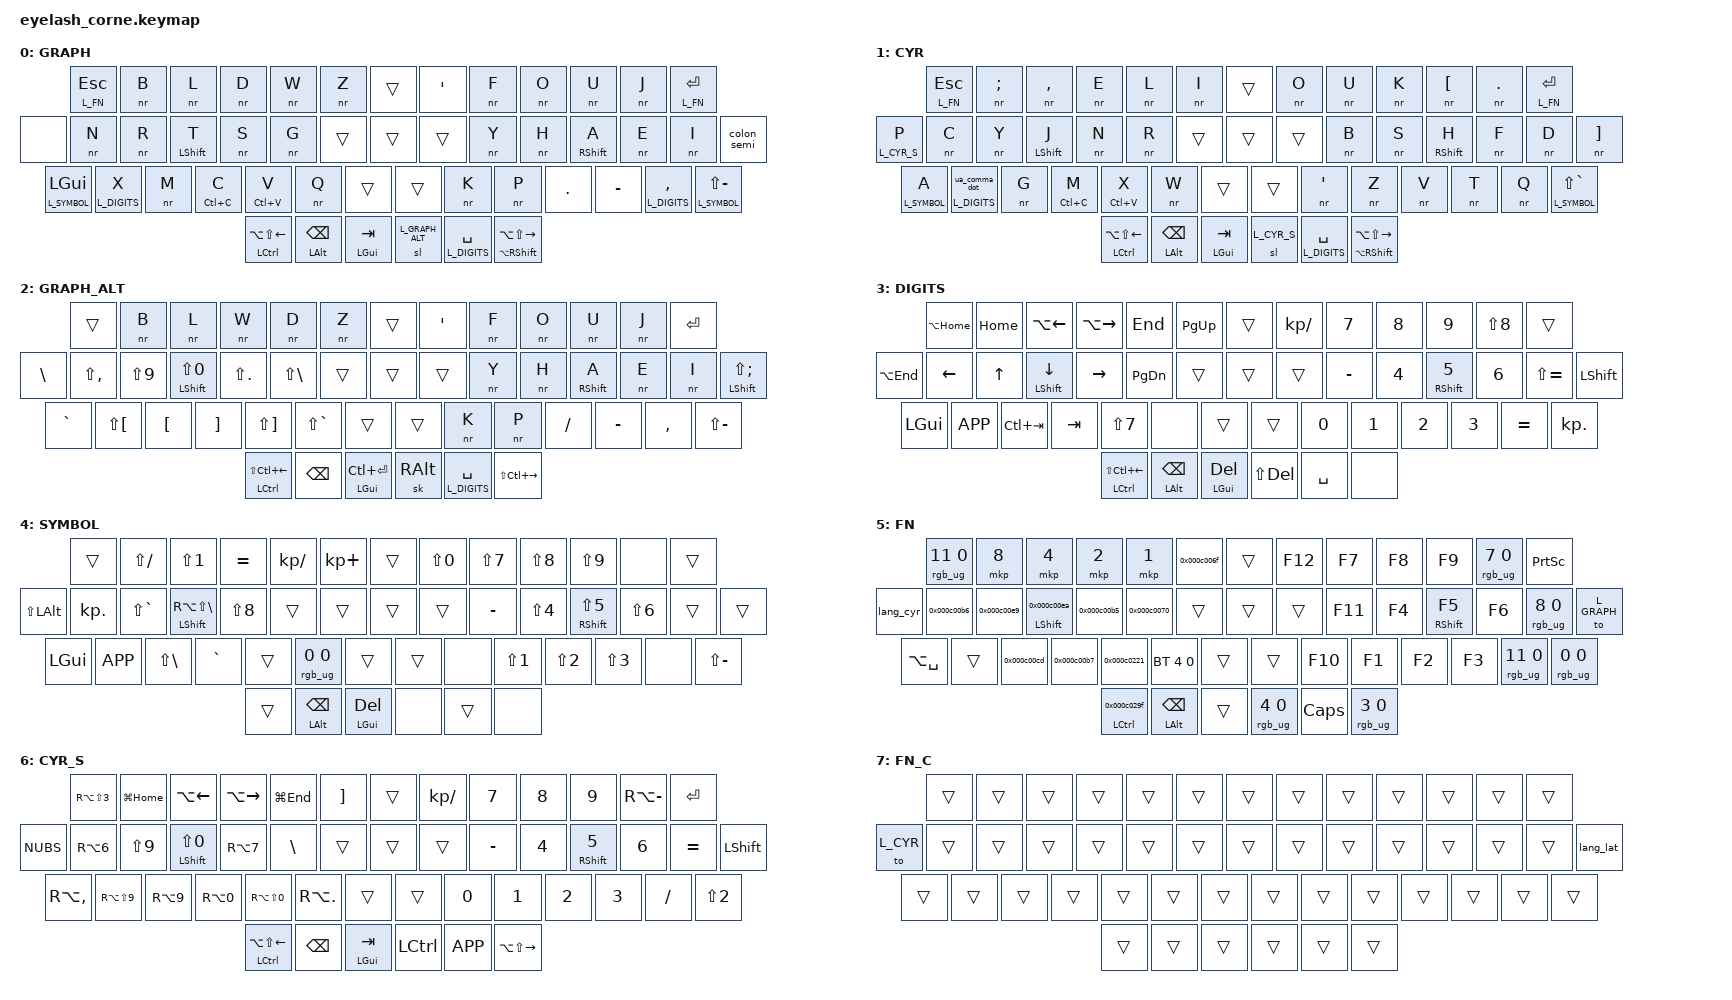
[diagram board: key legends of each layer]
/*
 * Згенеровано layout_dev_project/scripts/zmk/keymap_from_dump.py з дампу
 * клавіатури (ZMK Studio). Порядок шарів = пріоритет (нижчий у списку
 * перекриває вищі): CYR одразу після GRAPH, інакше він ховає DIGITS/SYMBOL/
 * FN/CYR_S. id у #define = позиція тут. 2026-11-17.
 */

#include <behaviors.dtsi>
#include <dt-bindings/zmk/keys.h>
#include <dt-bindings/zmk/bt.h>

#define L_GRAPH      0
#define L_GRAPH_ALT  2
#define L_DIGITS     3
#define L_SYMBOL     4
#define L_FN         5
#define L_CYR_S      6
#define L_CYR        1
#define L_FN_C       7

/ {
    behaviors {
        /* Tap = ESC, Hold = FN layer */
        esc_fn: esc_fn {
            compatible = "zmk,behavior-hold-tap";
            #binding-cells = <2>;
            tapping-term-ms = <200>;
            flavor = "balanced";
            bindings = <&kp>, <&mo>;
        };

        /* Home-row mods: холд лише якщо наступна клавіша на іншій руці / тхамбі
         * (перекат однією рукою = завжди тап) і лише після паузи в друці. */
        hml: home_row_mod_left {
            compatible = "zmk,behavior-hold-tap";
            display-name = "HRM Left";
            #binding-cells = <2>;
            flavor = "balanced";
            tapping-term-ms = <280>;
            quick-tap-ms = <175>;
            require-prior-idle-ms = <150>;
            hold-trigger-key-positions = <7 8 9 10 11 12 22 23 24 25 26 27 36 37 38 39 40 41 42 43 44 45 46 47>;
            hold-trigger-on-release;
            bindings = <&kp>, <&kp>;
        };

        hmr: home_row_mod_right {
            compatible = "zmk,behavior-hold-tap";
            display-name = "HRM Right";
            #binding-cells = <2>;
            flavor = "balanced";
            tapping-term-ms = <280>;
            quick-tap-ms = <175>;
            require-prior-idle-ms = <150>;
            hold-trigger-key-positions = <0 1 2 3 4 5 13 14 15 16 17 18 28 29 30 31 32 33 42 43 44 45 46 47>;
            hold-trigger-on-release;
            bindings = <&kp>, <&kp>;
        };

        /* Кирилиця (ua): тап ",", Shift+тап "." (шифт маскується, xkb ua дає
         * "." на голій FSLH). Стандарт ЙЦУКЕН навпаки — кома частіша. 2026-10-30. */
        ua_comma_dot: ua_comma_dot {
            compatible = "zmk,behavior-mod-morph";
            #binding-cells = <0>;
            bindings = <&kp LS(FSLH)>, <&kp FSLH>;
            mods = <(MOD_LSFT|MOD_RSFT)>;
        };

        /* Кома-крапка з холдом шару (як &lt): &lt_cd ШАР 0 */
        lt_cd: layer_tap_comma_dot {
            compatible = "zmk,behavior-hold-tap";
            display-name = "LT Comma/Dot";
            #binding-cells = <2>;
            flavor = "tap-preferred";
            tapping-term-ms = <200>;
            bindings = <&mo>, <&ua_comma_dot>;
        };

        /* Латиниця (us): тап ":", Shift+тап ";". 2026-10-30. */
        colon_semi: colon_semi {
            compatible = "zmk,behavior-mod-morph";
            display-name = "Colon/Semi";
            #binding-cells = <0>;
            bindings = <&kp LS(SEMI)>, <&kp SEMI>;
            mods = <(MOD_LSFT|MOD_RSFT)>;
        };

    };

    macros {
        /* Літери без автоповтору: на натискання — tap (press+release ~30 мс),
         * ОС не бачить затиснутої клавіші. BSPC/стрілки/пробіл тощо — &kp. 2026-11-17. */
        nr: no_repeat {
            compatible = "zmk,behavior-macro-one-param";
            display-name = "No Repeat";
            #binding-cells = <1>;
            bindings = <&macro_param_1to1 &macro_tap &kp MACRO_PLACEHOLDER>;
        };

        lang_tog: lang_toggle {
            compatible = "zmk,behavior-macro";
            display-name = "Lang Toggle";
            #binding-cells = <0>;
            bindings
                = <&tog L_CYR>
                , <&macro_press &kp LALT>
                , <&macro_tap &kp SPACE>
                , <&macro_release &kp LALT>
                ;
        };

        /* Мова ОС — перемикач Alt+Space (Linux: grp:alt_space_toggle; macOS:
         * Option+Space). Щоб шар і мова ОС не розходились, перемикач
         * надсилається лише тоді, коли мова справді змінюється: на FN (прийшли
         * з латиниці) Lang CYR = шар + Alt+Space, а →LAT — лише шар; на FN_C
         * (прийшли з кирилиці) навпаки. Розсинхрон (мову змінили мишкою) —
         * клавіша «Ресинк» на FN: лише Alt+Space. 2026-10-30. */
        lang_cyr: lang_cyr {
            compatible = "zmk,behavior-macro";
            display-name = "Lang CYR";
            #binding-cells = <0>;
            bindings = <&to L_CYR>, <&kp LA(SPACE)>;
        };

        lang_lat: lang_lat {
            compatible = "zmk,behavior-macro";
            display-name = "Lang LAT";
            #binding-cells = <0>;
            bindings = <&to L_GRAPH>, <&kp LA(SPACE)>;
        };

    };

    keymap {
        compatible = "zmk,keymap";

        layer_graph {
            display-name = "GRAPH";
            bindings = <
                /* верх */ &lt L_FN ESC  &nr B  &nr L  &nr D  &nr W  &nr Z  &trans  &kp SQT  &nr F  &nr O  &nr U  &nr J  &lt L_FN RET
                /* дім */ &none  &nr N  &nr R  &hml LSHFT T  &nr S  &nr G  &trans  &trans  &trans  &nr Y  &nr H  &hmr RSHFT A  &nr E  &nr I  &colon_semi
                /* низ */ &lt L_SYMBOL LGUI  &lt L_DIGITS X  &nr M  &hml LC(C) C  &hml LC(V) V  &nr Q  &trans  &trans  &nr K  &nr P  &kp DOT  &kp MINUS  &lt L_DIGITS COMMA  &lt L_SYMBOL LS(MINUS)
                /* тхамби */ &mt LCTRL LA(LS(LEFT))  &mt LALT BSPC  &mt LGUI TAB  &sl L_GRAPH_ALT  &lt L_DIGITS SPACE  &mt LA(RSHFT) LA(LS(RIGHT))
            >;
        };

        layer_cyr {
            display-name = "CYR";
            bindings = <
                /* верх */ &lt L_FN ESC  &nr SEMI  &nr COMMA  &nr E  &nr L  &nr I  &trans  &nr O  &nr U  &nr K  &nr LBKT  &nr DOT  &lt L_FN RET
                /* дім */ &lt L_CYR_S P  &nr C  &nr Y  &hml LSHFT J  &nr N  &nr R  &trans  &trans  &trans  &nr B  &nr S  &hmr RSHFT H  &nr F  &nr D  &nr RBKT
                /* низ */ &lt L_SYMBOL A  &lt_cd L_DIGITS 0  &nr G  &hml LC(C) M  &hml LC(V) X  &nr W  &trans  &trans  &nr SQT  &nr Z  &nr V  &nr T  &nr Q  &lt L_SYMBOL LS(GRAVE)
                /* тхамби */ &mt LCTRL LA(LS(LEFT))  &mt LALT BSPC  &mt LGUI TAB  &sl L_CYR_S  &lt L_DIGITS SPACE  &mt LA(RSHFT) LA(LS(RIGHT))
            >;
        };

        layer_graph_alt {
            display-name = "GRAPH_ALT";
            bindings = <
                /* верх */ &trans  &nr B  &nr L  &nr W  &nr D  &nr Z  &trans  &kp SQT  &nr F  &nr O  &nr U  &nr J  &kp RET
                /* дім */ &kp BSLH  &kp LS(COMMA)  &kp LS(N9)  &hml LSHFT LS(N0)  &kp LS(DOT)  &kp LS(BSLH)  &trans  &trans  &trans  &nr Y  &nr H  &hmr RSHFT A  &nr E  &nr I  &mt LSHFT LS(SEMI)
                /* низ */ &kp GRAVE  &kp LS(LBKT)  &kp LBKT  &kp RBKT  &kp LS(RBKT)  &kp LS(GRAVE)  &trans  &trans  &nr K  &nr P  &kp FSLH  &kp MINUS  &kp COMMA  &kp LS(MINUS)
                /* тхамби */ &mt LCTRL LS(LC(LEFT))  &kp BSPC  &mt LGUI LC(RET)  &sk RALT  &lt L_DIGITS SPACE  &kp LS(LC(RIGHT))
            >;
        };

        layer_digits {
            display-name = "DIGITS";
            bindings = <
                /* верх */ &kp LA(HOME)  &kp HOME  &kp LA(LEFT)  &kp LA(RIGHT)  &kp END  &kp PG_UP  &trans  &kp KP_SLASH  &kp N7  &kp N8  &kp N9  &kp LS(N8)  &trans
                /* дім */ &kp LA(END)  &kp LEFT  &kp UP  &hml LSHFT DOWN  &kp RIGHT  &kp PG_DN  &trans  &trans  &trans  &kp MINUS  &kp N4  &hmr RSHFT N5  &kp N6  &kp LS(EQUAL)  &kp LSHFT
                /* низ */ &kp LGUI  &kp K_APP  &kp LC(TAB)  &kp TAB  &kp LS(N7)  &none  &trans  &trans  &kp N0  &kp N1  &kp N2  &kp N3  &kp EQUAL  &kp KP_DOT
                /* тхамби */ &mt LCTRL LS(LC(LEFT))  &mt LALT BSPC  &mt LGUI DEL  &kp LS(DEL)  &kp SPACE  &none
            >;
        };

        layer_symbol {
            display-name = "SYMBOL";
            bindings = <
                /* верх */ &trans  &kp LS(FSLH)  &kp LS(N1)  &kp EQUAL  &kp KP_SLASH  &kp KP_PLUS  &trans  &kp LS(N0)  &kp LS(N7)  &kp LS(N8)  &kp LS(N9)  &none  &trans
                /* дім */ &kp LS(LALT)  &kp KP_DOT  &kp LS(GRAVE)  &hml LSHFT RA(LS(BSLH))  &kp LS(N8)  &trans  &trans  &trans  &trans  &kp MINUS  &kp LS(N4)  &hmr RSHFT LS(N5)  &kp LS(N6)  &trans  &trans
                /* низ */ &kp LGUI  &kp K_APP  &kp LS(BSLH)  &kp GRAVE  &trans  &rgb_ug 0 0  &trans  &trans  &none  &kp LS(N1)  &kp LS(N2)  &kp LS(N3)  &none  &kp LS(MINUS)
                /* тхамби */ &trans  &mt LALT BSPC  &mt LGUI DEL  &none  &trans  &none
            >;
        };

        layer_fn {
            display-name = "FN";
            bindings = <
                /* верх */ &rgb_ug 11 0  &mkp 8  &mkp 4  &mkp 2  &mkp 1  &kp 0x000c006f  &trans  &kp F12  &kp F7  &kp F8  &kp F9  &rgb_ug 7 0  &kp PSCRN
                /* дім */ &lang_cyr  &kp 0x000c00b6  &kp 0x000c00e9  &hml LSHFT 0x000c00ea  &kp 0x000c00b5  &kp 0x000c0070  &trans  &trans  &trans  &kp F11  &kp F4  &hmr RSHFT F5  &kp F6  &rgb_ug 8 0  &to L_GRAPH
                /* низ */ &kp LA(SPACE)  &trans  &kp 0x000c00cd  &kp 0x000c00b7  &kp 0x000c0221  &bt 4 0  &trans  &trans  &kp F10  &kp F1  &kp F2  &kp F3  &rgb_ug 11 0  &rgb_ug 0 0
                /* тхамби */ &mt LCTRL 0x000c029f  &mt LALT BSPC  &trans  &rgb_ug 4 0  &kp CAPS  &rgb_ug 3 0
            >;
        };

        layer_cyr_s {
            display-name = "CYR_S";
            bindings = <
                /* верх */ &kp RA(LS(N3))  &kp LG(HOME)  &kp LA(LEFT)  &kp LA(RIGHT)  &kp LG(END)  &kp RBKT  &trans  &kp KP_SLASH  &kp N7  &kp N8  &kp N9  &kp RA(MINUS)  &kp RET
                /* дім */ &kp NUBS  &kp RA(N6)  &kp LS(N9)  &hml LSHFT LS(N0)  &kp RA(N7)  &kp BSLH  &trans  &trans  &trans  &kp MINUS  &kp N4  &hmr RSHFT N5  &kp N6  &kp EQUAL  &kp LSHFT
                /* низ */ &kp RA(COMMA)  &kp RA(LS(N9))  &kp RA(N9)  &kp RA(N0)  &kp RA(LS(N0))  &kp RA(DOT)  &trans  &trans  &kp N0  &kp N1  &kp N2  &kp N3  &kp FSLH  &kp LS(N2)
                /* тхамби */ &mt LCTRL LA(LS(LEFT))  &kp BSPC  &mt LGUI TAB  &kp LCTRL  &kp K_APP  &kp LA(LS(RIGHT))
            >;
        };

        layer_fn_c {
            display-name = "FN_C";
            bindings = <
                /* верх */ &trans  &trans  &trans  &trans  &trans  &trans  &trans  &trans  &trans  &trans  &trans  &trans  &trans
                /* дім */ &to L_CYR  &trans  &trans  &trans  &trans  &trans  &trans  &trans  &trans  &trans  &trans  &trans  &trans  &trans  &lang_lat
                /* низ */ &trans  &trans  &trans  &trans  &trans  &trans  &trans  &trans  &trans  &trans  &trans  &trans  &trans  &trans
                /* тхамби */ &trans  &trans  &trans  &trans  &trans  &trans
            >;
        };
    };
    conditional_layers {
        compatible = "zmk,conditional-layers";
        fn_from_cyr {
            if-layers = <L_CYR L_FN>;
            then-layer = <L_FN_C>;
        };
    };
};
